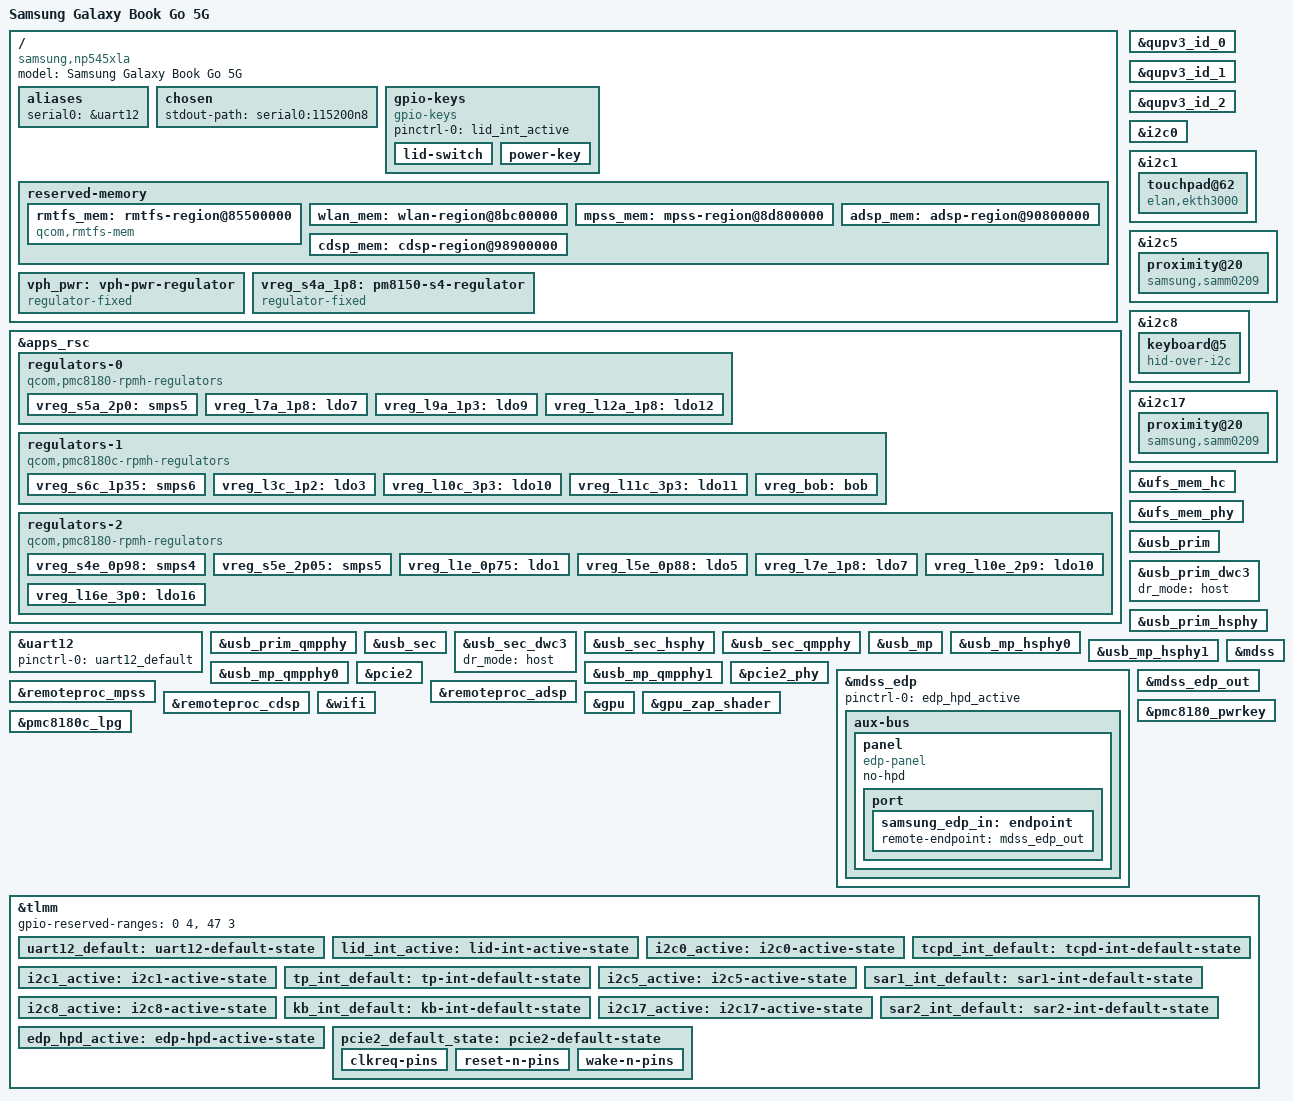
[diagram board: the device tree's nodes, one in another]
// SPDX-License-Identifier: BSD-3-Clause
/*
 * Samsung Galaxy Book Go 5G (NP545XLA) device tree
 *
 * SoC: Qualcomm Snapdragon 8cx Gen 2 (SC8180XP)
 *
 * GPIO and I2C mappings extracted from Samsung ACPI DSDT dump.
 * See acpi-dts-map.md for full source data.
 *
 * ACPI GPIO pins 640 (keyboard) and 448 (USB-C PD) are beyond TLMM
 * range (0-191). These need runtime verification.
 *
 * Copyright (c) 2025, the NP545XLA Linux contributors
 */

/dts-v1/;

#include <dt-bindings/firmware/qcom,scm.h>
#include <dt-bindings/gpio/gpio.h>
#include <dt-bindings/input/gpio-keys.h>
#include <dt-bindings/input/input.h>
#include <dt-bindings/regulator/qcom,rpmh-regulator.h>
#include "sc8180x.dtsi"
#include "sc8180x-pmics.dtsi"

/ {
	model = "Samsung Galaxy Book Go 5G";
	compatible = "samsung,np545xla", "qcom,sc8180x";

	aliases {
		serial0 = &uart12;
	};

	chosen {
		stdout-path = "serial0:115200n8";
	};

	gpio-keys {
		compatible = "gpio-keys";

		pinctrl-0 = <&lid_int_active>;
		pinctrl-names = "default";

		lid-switch {
			gpios = <&tlmm 50 GPIO_ACTIVE_LOW>;
			linux,input-type = <EV_SW>;
			linux,code = <SW_LID>;
			wakeup-source;
		};

		power-key {
			gpios = <&pmc8180_pwrkey 0 GPIO_ACTIVE_LOW>;
			linux,code = <KEY_POWER>;
			wakeup-source;
		};
	};

	reserved-memory {
		rmtfs_mem: rmtfs-region@85500000 {
			compatible = "qcom,rmtfs-mem";
			reg = <0x0 0x85500000 0x0 0x200000>;
			no-map;

			qcom,client-id = <1>;
			qcom,vmid = <QCOM_SCM_VMID_MSS_MSA>;
		};

		wlan_mem: wlan-region@8bc00000 {
			reg = <0x0 0x8bc00000 0x0 0x180000>;
			no-map;
		};

		mpss_mem: mpss-region@8d800000 {
			reg = <0x0 0x8d800000 0x0 0x3000000>;
			no-map;
		};

		adsp_mem: adsp-region@90800000 {
			reg = <0x0 0x90800000 0x0 0x1c00000>;
			no-map;
		};

		cdsp_mem: cdsp-region@98900000 {
			reg = <0x0 0x98900000 0x0 0x1400000>;
			no-map;
		};
	};

	vph_pwr: vph-pwr-regulator {
		compatible = "regulator-fixed";
		regulator-name = "vph_pwr";
		regulator-min-microvolt = <3700000>;
		regulator-max-microvolt = <3700000>;
	};

	vreg_s4a_1p8: pm8150-s4-regulator {
		compatible = "regulator-fixed";
		regulator-name = "vreg_s4a_1p8";
		regulator-min-microvolt = <1800000>;
		regulator-max-microvolt = <1800000>;
		regulator-always-on;
		regulator-boot-on;
		vin-supply = <&vph_pwr>;
	};
};

/* ==================== PSCI Workaround ==================== */
/* apps_rsc has power-domains = <&cluster_pd> from the dtsi.
 * If PSCI firmware doesn't properly provide cluster_pd, all RPMH
 * regulators and clocks fail to probe, causing a cascade of
 * deferred probes (GCC, SMMU, USB, interconnects, etc.).
 * Remove the power-domains dependency as a workaround.
 */
&apps_rsc {
	/delete-property/ power-domains;
};

/* PMIC regulators — copied from Lenovo Flex 5G as starting point */
/* TODO: Verify against Samsung hardware. PMIC topology should be
 * identical (pmc8180 + pmc8180c), but individual rail voltages
 * and loads may differ. Adjust as needed.
 */
&apps_rsc {
	regulators-0 {
		compatible = "qcom,pmc8180-rpmh-regulators";
		qcom,pmic-id = "a";

		vdd-s5-supply = <&vph_pwr>;
		vdd-l7-l12-l14-l15-supply = <&vreg_s5a_2p0>;

		vreg_s5a_2p0: smps5 {
			regulator-min-microvolt = <2040000>;
			regulator-max-microvolt = <2100000>;
		};

		vreg_l7a_1p8: ldo7 {
			regulator-min-microvolt = <1800000>;
			regulator-max-microvolt = <1800000>;
			regulator-initial-mode = <RPMH_REGULATOR_MODE_HPM>;
		};

		vreg_l9a_1p3: ldo9 {
			regulator-min-microvolt = <1296000>;
			regulator-max-microvolt = <1304000>;
			regulator-initial-mode = <RPMH_REGULATOR_MODE_HPM>;
		};

		vreg_l12a_1p8: ldo12 {
			regulator-min-microvolt = <1800000>;
			regulator-max-microvolt = <1800000>;
			regulator-initial-mode = <RPMH_REGULATOR_MODE_HPM>;
		};
	};

	regulators-1 {
		compatible = "qcom,pmc8180c-rpmh-regulators";
		qcom,pmic-id = "c";

		vdd-s6-supply = <&vph_pwr>;
		vdd-l2-l3-supply = <&vreg_s6c_1p35>;
		vdd-bob-supply = <&vph_pwr>;

		vreg_s6c_1p35: smps6 {
			regulator-min-microvolt = <1350000>;
			regulator-max-microvolt = <1372000>;
			regulator-initial-mode = <RPMH_REGULATOR_MODE_HPM>;
		};

		vreg_l3c_1p2: ldo3 {
			regulator-min-microvolt = <1200000>;
			regulator-max-microvolt = <1200000>;
			regulator-initial-mode = <RPMH_REGULATOR_MODE_HPM>;
		};

		vreg_l10c_3p3: ldo10 {
			regulator-min-microvolt = <3000000>;
			regulator-max-microvolt = <3312000>;
			regulator-initial-mode = <RPMH_REGULATOR_MODE_HPM>;
		};

		vreg_l11c_3p3: ldo11 {
			regulator-min-microvolt = <3296000>;
			regulator-max-microvolt = <3304000>;
			regulator-initial-mode = <RPMH_REGULATOR_MODE_HPM>;
		};

		vreg_bob: bob {
			regulator-min-microvolt = <3296000>;
			regulator-max-microvolt = <3350000>;
			regulator-initial-mode = <RPMH_REGULATOR_MODE_HPM>;
		};
	};

	regulators-2 {
		compatible = "qcom,pmc8180-rpmh-regulators";
		qcom,pmic-id = "e";

		vdd-s4-supply = <&vph_pwr>;
		vdd-s5-supply = <&vph_pwr>;
		vdd-l2-l10-supply = <&vreg_bob>;
		vdd-l3-l4-l5-l18-supply = <&vreg_s4e_0p98>;
		vdd-l7-l12-l14-l15-supply = <&vreg_s5e_2p05>;
		vdd-l13-l16-l17-supply = <&vreg_bob>;

		vreg_s4e_0p98: smps4 {
			regulator-min-microvolt = <992000>;
			regulator-max-microvolt = <992000>;
			regulator-initial-mode = <RPMH_REGULATOR_MODE_HPM>;
		};

		vreg_s5e_2p05: smps5 {
			regulator-min-microvolt = <2040000>;
			regulator-max-microvolt = <2040000>;
			regulator-initial-mode = <RPMH_REGULATOR_MODE_HPM>;
		};

		vreg_l1e_0p75: ldo1 {
			regulator-min-microvolt = <752000>;
			regulator-max-microvolt = <752000>;
			regulator-initial-mode = <RPMH_REGULATOR_MODE_HPM>;
		};

		vreg_l5e_0p88: ldo5 {
			regulator-min-microvolt = <880000>;
			regulator-max-microvolt = <880000>;
			regulator-initial-mode = <RPMH_REGULATOR_MODE_HPM>;
		};

		vreg_l7e_1p8: ldo7 {
			regulator-min-microvolt = <1800000>;
			regulator-max-microvolt = <1800000>;
			regulator-initial-mode = <RPMH_REGULATOR_MODE_HPM>;
			regulator-allowed-modes = <RPMH_REGULATOR_MODE_LPM
						   RPMH_REGULATOR_MODE_HPM>;
			regulator-allow-set-load;
		};

		vreg_l10e_2p9: ldo10 {
			regulator-min-microvolt = <2904000>;
			regulator-max-microvolt = <2904000>;
			regulator-initial-mode = <RPMH_REGULATOR_MODE_HPM>;
			regulator-allowed-modes = <RPMH_REGULATOR_MODE_LPM
						   RPMH_REGULATOR_MODE_HPM>;
			regulator-allow-set-load;
		};

		vreg_l16e_3p0: ldo16 {
			regulator-min-microvolt = <3072000>;
			regulator-max-microvolt = <3072000>;
			regulator-initial-mode = <RPMH_REGULATOR_MODE_HPM>;
		};
	};
};

/* ==================== QUP / I2C / UART ==================== */

&qupv3_id_0 {
	status = "okay";
};

&qupv3_id_1 {
	status = "okay";
};

&qupv3_id_2 {
	status = "okay";
};

/* I2C0 (QUP0 SE0) — USB-C PD controller (TCPD)
 * ACPI gpio448 is beyond TLMM range — disabled until pin verified
 */
&i2c0 {
	clock-frequency = <400000>;

	pinctrl-0 = <&i2c0_active>;
	pinctrl-names = "default";

	status = "okay";

	/* USB-C PD controller — IRQ pin TBD (ACPI gpio448, needs mapping) */
	/* Uncomment when IRQ pin is verified:
	usb-pd@40 {
		compatible = "hid-over-i2c";
		reg = <0x40>;
		hid-descr-addr = <0x1>;
		interrupts-extended = <&tlmm XX IRQ_TYPE_LEVEL_LOW>;
		pinctrl-0 = <&tcpd_int_default>;
		pinctrl-names = "default";
	};
	*/
};

/* I2C1 (QUP0 SE1) — Touchpad (ECTC) */
&i2c1 {
	clock-frequency = <400000>;

	pinctrl-0 = <&i2c1_active>;
	pinctrl-names = "default";

	status = "okay";

	touchpad@62 {
		compatible = "elan,ekth3000", "hid-over-i2c";
		reg = <0x62>;
		hid-descr-addr = <0x1>;

		/* ACPI: gpio118 — confirmed valid TLMM pin */
		interrupts-extended = <&tlmm 118 IRQ_TYPE_LEVEL_LOW>;

		pinctrl-0 = <&tp_int_default>;
		pinctrl-names = "default";
	};
};

/* I2C5 (QUP0 SE5) — SAR proximity sensor 1 */
&i2c5 {
	clock-frequency = <400000>;

	pinctrl-0 = <&i2c5_active>;
	pinctrl-names = "default";

	status = "okay";

	proximity@20 {
		compatible = "samsung,samm0209";
		reg = <0x20>;

		interrupts-extended = <&tlmm 93 IRQ_TYPE_EDGE_FALLING>;

		pinctrl-0 = <&sar1_int_default>;
		pinctrl-names = "default";
	};
};

/* I2C8 (QUP1 SE0) — Keyboard (ECKB)
 * ACPI I2C9 at 0x00A80000 = DT i2c8 (QUP1 SE0), pins gpio88/gpio89
 */
&i2c8 {
	clock-frequency = <400000>;

	pinctrl-0 = <&i2c8_active>;
	pinctrl-names = "default";

	status = "okay";

	keyboard@5 {
		compatible = "hid-over-i2c";
		reg = <0x05>;
		hid-descr-addr = <0x1>;

		/* ACPI: gpio640 — needs verification. Not gpio89 (I2C SDA).
		 * Likely a different TLMM pin or PMIC GPIO.
		 */
		interrupts-extended = <&tlmm 91 IRQ_TYPE_LEVEL_LOW>;

		pinctrl-0 = <&kb_int_default>;
		pinctrl-names = "default";
	};
};

/* I2C17 (QUP2 SE1) — SAR proximity sensor 2
 * ACPI IC18 at 0x00C80000 = DT i2c17 (QUP2 SE1), pins gpio55/gpio56
 */
&i2c17 {
	clock-frequency = <400000>;

	pinctrl-0 = <&i2c17_active>;
	pinctrl-names = "default";

	status = "okay";

	proximity@20 {
		compatible = "samsung,samm0209";
		reg = <0x20>;

		interrupts-extended = <&tlmm 87 IRQ_TYPE_EDGE_FALLING>;

		pinctrl-0 = <&sar2_int_default>;
		pinctrl-names = "default";
	};
};

/* Debug UART — 3.5mm combo jack, QUP1 SE10 */
&uart12 {
	pinctrl-0 = <&uart12_default>;
	pinctrl-names = "default";

	status = "okay";
};

/* ==================== UFS ==================== */

&ufs_mem_hc {
	reset-gpios = <&tlmm 190 GPIO_ACTIVE_LOW>;

	vcc-supply = <&vreg_l10e_2p9>;
	vcc-max-microamp = <155000>;

	vccq2-supply = <&vreg_l7e_1p8>;
	vccq2-max-microamp = <425000>;

	status = "okay";
};

&ufs_mem_phy {
	vdda-phy-supply = <&vreg_l5e_0p88>;
	vdda-pll-supply = <&vreg_l3c_1p2>;

	status = "okay";
};

/* ==================== USB ==================== */

/* Primary USB (USB-C port 1) */
&usb_prim {
	status = "okay";
};

&usb_prim_dwc3 {
	dr_mode = "host";
};

&usb_prim_hsphy {
	vdda-pll-supply = <&vreg_l5e_0p88>;
	vdda18-supply = <&vreg_l12a_1p8>;
	vdda33-supply = <&vreg_l16e_3p0>;

	status = "okay";
};

&usb_prim_qmpphy {
	vdda-phy-supply = <&vreg_l3c_1p2>;
	vdda-pll-supply = <&vreg_l5e_0p88>;

	status = "okay";
};

/* Secondary USB (USB-C port 2) */
&usb_sec {
	status = "okay";
};

&usb_sec_dwc3 {
	dr_mode = "host";
};

&usb_sec_hsphy {
	vdda-pll-supply = <&vreg_l5e_0p88>;
	vdda18-supply = <&vreg_l12a_1p8>;
	vdda33-supply = <&vreg_l16e_3p0>;

	status = "okay";
};

&usb_sec_qmpphy {
	vdda-phy-supply = <&vreg_l3c_1p2>;
	vdda-pll-supply = <&vreg_l5e_0p88>;

	status = "okay";
};

/* Mid-speed USB (USB-A port) */
&usb_mp {
	status = "okay";
};

&usb_mp_hsphy0 {
	vdda-pll-supply = <&vreg_l5e_0p88>;
	vdda18-supply = <&vreg_l12a_1p8>;
	vdda33-supply = <&vreg_l16e_3p0>;

	status = "okay";
};

&usb_mp_hsphy1 {
	vdda-pll-supply = <&vreg_l5e_0p88>;
	vdda18-supply = <&vreg_l12a_1p8>;
	vdda33-supply = <&vreg_l16e_3p0>;

	status = "okay";
};

&usb_mp_qmpphy0 {
	vdda-phy-supply = <&vreg_l3c_1p2>;
	vdda-pll-supply = <&vreg_l5e_0p88>;

	status = "okay";
};

&usb_mp_qmpphy1 {
	vdda-phy-supply = <&vreg_l3c_1p2>;
	vdda-pll-supply = <&vreg_l5e_0p88>;

	status = "okay";
};

/* ==================== PCIe ==================== */

/* PCIe2 — WiFi (ACPI PNID=2, confirmed from DSDT) */
&pcie2 {
	perst-gpios = <&tlmm 175 GPIO_ACTIVE_LOW>;
	wake-gpios = <&tlmm 35 GPIO_ACTIVE_HIGH>;
	pinctrl-0 = <&pcie2_default_state>;
	pinctrl-names = "default";

	status = "okay";
};

&pcie2_phy {
	vdda-phy-supply = <&vreg_l5e_0p88>;
	vdda-pll-supply = <&vreg_l3c_1p2>;

	status = "okay";
};

/* ==================== Display ==================== */

&mdss {
	status = "okay";
};

&mdss_edp {
	pinctrl-0 = <&edp_hpd_active>;
	pinctrl-names = "default";

	status = "okay";

	aux-bus {
		panel {
			compatible = "edp-panel";
			no-hpd;

			port {
				samsung_edp_in: endpoint {
					remote-endpoint = <&mdss_edp_out>;
				};
			};
		};
	};
};

&mdss_edp_out {
	data-lanes = <0 1 2 3>;
	remote-endpoint = <&samsung_edp_in>;
};

/* ==================== Remoteprocs ==================== */

&remoteproc_mpss {
	memory-region = <&mpss_mem>;
	firmware-name = "qcom/sc8180x/SAMSUNG/NP545XLA/qcmpss8180_nm.mbn";

	status = "okay";
};

&remoteproc_adsp {
	memory-region = <&adsp_mem>;
	firmware-name = "qcom/sc8180x/SAMSUNG/NP545XLA/qcadsp8180.mbn";

	status = "okay";
};

&remoteproc_cdsp {
	memory-region = <&cdsp_mem>;
	firmware-name = "qcom/sc8180x/SAMSUNG/NP545XLA/qccdsp8180.mbn";

	status = "okay";
};

/* ==================== WiFi ==================== */

&wifi {
	memory-region = <&wlan_mem>;

	vdd-0.8-cx-mx-supply = <&vreg_l1e_0p75>;
	vdd-1.8-xo-supply = <&vreg_l7a_1p8>;
	vdd-1.3-rfa-supply = <&vreg_l9a_1p3>;
	vdd-3.3-ch0-supply = <&vreg_l11c_3p3>;
	vdd-3.3-ch1-supply = <&vreg_l10c_3p3>;

	status = "okay";
};

/* ==================== GPU ==================== */

&gpu {
	status = "okay";
};

&gpu_zap_shader {
	firmware-name = "qcom/sc8180x/SAMSUNG/NP545XLA/qcdxkmsuc8180.mbn";
};

/* ==================== PMIC ==================== */

&pmc8180_pwrkey {
	status = "okay";
};

&pmc8180c_lpg {
	status = "okay";
};

/* ==================== PINCTRL ==================== */

&tlmm {
	/*
	 * Samsung uses gpio50 for the lid switch (confirmed from DSDT LIDR field).
	 * The Lenovo Flex 5G reserves gpio47-50, but Samsung does NOT.
	 * Only reserve gpio0-3 (trustzone) and gpio47-49.
	 */
	gpio-reserved-ranges = <0 4>, <47 3>;

	uart12_default: uart12-default-state {
		pins = "gpio83", "gpio84";
		function = "qup12";
		drive-strength = <2>;
		bias-disable;
	};

	lid_int_active: lid-int-active-state {
		pins = "gpio50";
		function = "gpio";
		bias-pull-up;
		drive-strength = <2>;
	};

	/* I2C0 — USB-C PD controller */
	i2c0_active: i2c0-active-state {
		pins = "gpio0", "gpio1";
		function = "qup0";
		bias-pull-up;
		drive-strength = <2>;
	};

	tcpd_int_default: tcpd-int-default-state {
		/* ACPI:gpio448 — TBD, PMIC or tile-offset pin */
		pins = "gpio4"; /* placeholder — needs verification */
		function = "gpio";
		bias-pull-up;
		drive-strength = <2>;
	};

	/* I2C1 — Touchpad */
	i2c1_active: i2c1-active-state {
		pins = "gpio114", "gpio115";
		function = "qup1";
		bias-pull-up;
		drive-strength = <2>;
	};

	tp_int_default: tp-int-default-state {
		pins = "gpio118";
		function = "gpio";
		bias-pull-up;
		drive-strength = <2>;
	};

	/* I2C5 — SAR sensor 1 (QUP0 SE5, pins gpio119/gpio120) */
	i2c5_active: i2c5-active-state {
		pins = "gpio119", "gpio120";
		function = "qup5";
		bias-pull-up;
		drive-strength = <2>;
	};

	sar1_int_default: sar1-int-default-state {
		pins = "gpio93";
		function = "gpio";
		bias-pull-up;
		drive-strength = <2>;
	};

	/* I2C8 — Keyboard (QUP1 SE0, pins gpio88/gpio89) */
	i2c8_active: i2c8-active-state {
		pins = "gpio88", "gpio89";
		function = "qup8";
		bias-pull-up;
		drive-strength = <2>;
	};

	kb_int_default: kb-int-default-state {
		pins = "gpio91"; /* ACPI:640 — needs verification */
		function = "gpio";
		bias-pull-up;
		drive-strength = <2>;
	};

	/* I2C17 — SAR sensor 2 (QUP2 SE1, pins gpio55/gpio56) */
	i2c17_active: i2c17-active-state {
		pins = "gpio55", "gpio56";
		function = "qup17";
		bias-pull-up;
		drive-strength = <2>;
	};

	sar2_int_default: sar2-int-default-state {
		pins = "gpio87";
		function = "gpio";
		bias-pull-up;
		drive-strength = <2>;
	};

	/* eDP HPD */
	edp_hpd_active: edp-hpd-active-state {
		pins = "gpio10";
		function = "edp_hot";
	};

	/* PCIe2 — WiFi */
	pcie2_default_state: pcie2-default-state {
		clkreq-pins {
			pins = "gpio102";
			function = "pci_e2";
			bias-pull-up;
		};

		reset-n-pins {
			pins = "gpio175";
			function = "gpio";
			drive-strength = <2>;
			output-low;
			bias-pull-down;
		};

		wake-n-pins {
			pins = "gpio35";
			function = "gpio";
			drive-strength = <2>;
			bias-pull-up;
		};
	};
};
